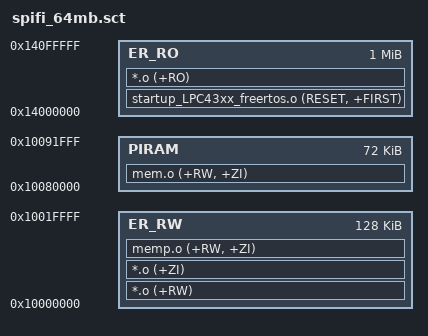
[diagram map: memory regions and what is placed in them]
;-------------------------------------------------------------------------------------
;   Keil scatter loading file
;-------------------------------------------------------------------------------------

; Load region is in SPI FLASH
FLASH 0x14000000 0x100000 {
  ; All code and RO data in SPI FLASH
  ER_RO 0x14000000 0x100000 {
    startup_LPC43xx_freertos.o (RESET, +FIRST)
    *.o (+RO)
  }

  ; IRAM for data
  ER_RW 0x10000000 0x20000 {
    *.o (+RW)
    *.o (+ZI)
	memp.o (+RW, +ZI)
  }

  ; DMA buffers need to be located in peripheral RAM, but not pbufs
  PIRAM 0x10080000 0x00012000 {
	mem.o (+RW, +ZI)
  }
}
